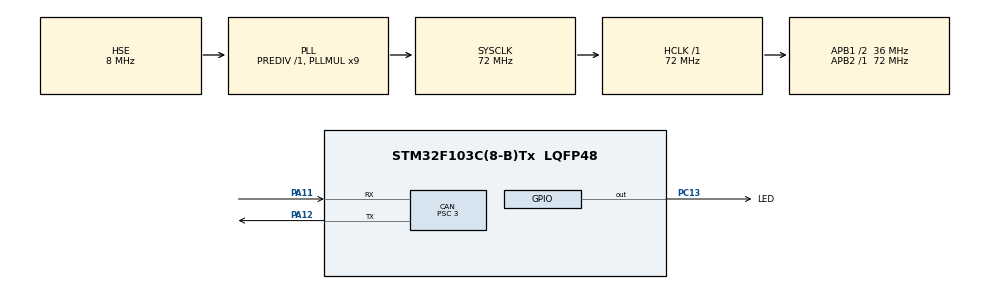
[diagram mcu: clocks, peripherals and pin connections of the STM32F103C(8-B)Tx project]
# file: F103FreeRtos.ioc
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CAN.BS1=CAN_BS1_9TQ
CAN.BS2=CAN_BS2_2TQ
CAN.CalculateTimeBit=1000
CAN.CalculateTimeQuantum=83.33333333333334
CAN.Prescaler=3
FREERTOS.Tasks01=defaultTask,0,128,StartDefaultTask,Default,NULL
Mcu.Family=STM32F1
Mcu.Name=STM32F103C(8-B)Tx
Mcu.Package=LQFP48
NVIC.PriorityGroup=NVIC_PRIORITYGROUP_4
NVIC.TIM4_IRQn=true\:0\:0\:false\:false\:true\:false\:false\:true
NVIC.TimeBase=TIM4_IRQn
NVIC.TimeBaseIP=TIM4
PA11.Mode=Master
PA11.Signal=CAN_RX
PA12.Mode=Master
PA12.Signal=CAN_TX
PA13.Mode=Serial_Wire
PA13.Signal=SYS_JTMS-SWDIO
PA14.Mode=Serial_Wire
PA14.Signal=SYS_JTCK-SWCLK
PC13-TAMPER-RTC.GPIO_Label=LED
PC13-TAMPER-RTC.Signal=GPIO_Output
PC14-OSC32_IN.Mode=LSE-External-Oscillator
PC14-OSC32_IN.Signal=RCC_OSC32_IN
PC15-OSC32_OUT.Mode=LSE-External-Oscillator
PC15-OSC32_OUT.Signal=RCC_OSC32_OUT
PD0-OSC_IN.Mode=HSE-External-Oscillator
PD0-OSC_IN.Signal=RCC_OSC_IN
PD1-OSC_OUT.Mode=HSE-External-Oscillator
PD1-OSC_OUT.Signal=RCC_OSC_OUT
ProjectManager.HeapSize=0x200
ProjectManager.StackSize=0x400
ProjectManager.TargetToolchain=Makefile
RCC.AHBFreq_Value=72000000
RCC.APB1CLKDivider=RCC_HCLK_DIV2
RCC.APB1Freq_Value=36000000
RCC.APB1TimFreq_Value=72000000
RCC.APB2Freq_Value=72000000
RCC.APB2TimFreq_Value=72000000
RCC.HCLKFreq_Value=72000000
RCC.PLLMUL=RCC_PLL_MUL9
RCC.PLLSourceVirtual=RCC_PLLSOURCE_HSE
RCC.SYSCLKFreq_VALUE=72000000
RCC.SYSCLKSource=RCC_SYSCLKSOURCE_PLLCLK
RCC.USBFreq_Value=72000000
VP_FREERTOS_VS_CMSIS_V1.Mode=CMSIS_V1
VP_SYS_VS_tim4.Mode=TIM4
board=custom

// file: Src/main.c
/* USER CODE BEGIN Header */
/**
  ******************************************************************************
  * @file           : main.c
  * @brief          : Main program body
  ******************************************************************************
  * @attention
  *
  * <h2><center>&copy; Copyright (c) 2019 STMicroelectronics.
  * All rights reserved.</center></h2>
  *
  * This software component is licensed by ST under Ultimate Liberty license
  * SLA0044, the "License"; You may not use this file except in compliance with
  * the License. You may obtain a copy of the License at:
  *                             www.st.com/SLA0044
  *
  ******************************************************************************
  */
/* USER CODE END Header */

#include "main.h"
#include "cmsis_os.h"

CAN_HandleTypeDef hcan;

osThreadId defaultTaskHandle;

void SystemClock_Config(void);
static void MX_GPIO_Init(void);
static void MX_CAN_Init(void);
void StartDefaultTask(void const * argument);

int main(void)
{

  /* MCU Configuration--------------------------------------------------------*/

  /* Reset of all peripherals, Initializes the Flash interface and the Systick. */
  HAL_Init();

  /* Configure the system clock */
  SystemClock_Config();

  /* Initialize all configured peripherals */
  MX_GPIO_Init();
  MX_CAN_Init();

  /* Create the thread(s) */
  /* definition and creation of defaultTask */
  osThreadDef(defaultTask, StartDefaultTask, osPriorityNormal, 0, 128);
  defaultTaskHandle = osThreadCreate(osThread(defaultTask), NULL);

  /* Start scheduler */
  osKernelStart();

  /* We should never get here as control is now taken by the scheduler */

  /* Infinite loop */
  while (1)
  {

  }
}

void SystemClock_Config(void)
{
  RCC_OscInitTypeDef RCC_OscInitStruct = {0};
  RCC_ClkInitTypeDef RCC_ClkInitStruct = {0};

  /** Initializes the CPU, AHB and APB busses clocks
  */
  RCC_OscInitStruct.OscillatorType = RCC_OSCILLATORTYPE_HSE;
  RCC_OscInitStruct.HSEState = RCC_HSE_ON;
  RCC_OscInitStruct.HSEPredivValue = RCC_HSE_PREDIV_DIV1;
  RCC_OscInitStruct.HSIState = RCC_HSI_ON;
  RCC_OscInitStruct.PLL.PLLState = RCC_PLL_ON;
  RCC_OscInitStruct.PLL.PLLSource = RCC_PLLSOURCE_HSE;
  RCC_OscInitStruct.PLL.PLLMUL = RCC_PLL_MUL9;
  if (HAL_RCC_OscConfig(&RCC_OscInitStruct) != HAL_OK)
  {
    Error_Handler();
  }
  /** Initializes the CPU, AHB and APB busses clocks
  */
  RCC_ClkInitStruct.ClockType = RCC_CLOCKTYPE_HCLK|RCC_CLOCKTYPE_SYSCLK
                              |RCC_CLOCKTYPE_PCLK1|RCC_CLOCKTYPE_PCLK2;
  RCC_ClkInitStruct.SYSCLKSource = RCC_SYSCLKSOURCE_PLLCLK;
  RCC_ClkInitStruct.AHBCLKDivider = RCC_SYSCLK_DIV1;
  RCC_ClkInitStruct.APB1CLKDivider = RCC_HCLK_DIV2;
  RCC_ClkInitStruct.APB2CLKDivider = RCC_HCLK_DIV1;

  if (HAL_RCC_ClockConfig(&RCC_ClkInitStruct, FLASH_LATENCY_2) != HAL_OK)
  {
    Error_Handler();
  }
}

static void MX_CAN_Init(void)
{

  hcan.Instance = CAN1;
  hcan.Init.Prescaler = 3;
  hcan.Init.Mode = CAN_MODE_NORMAL;
  hcan.Init.SyncJumpWidth = CAN_SJW_1TQ;
  hcan.Init.TimeSeg1 = CAN_BS1_9TQ;
  hcan.Init.TimeSeg2 = CAN_BS2_2TQ;
  hcan.Init.TimeTriggeredMode = DISABLE;
  hcan.Init.AutoBusOff = DISABLE;
  hcan.Init.AutoWakeUp = DISABLE;
  hcan.Init.AutoRetransmission = DISABLE;
  hcan.Init.ReceiveFifoLocked = DISABLE;
  hcan.Init.TransmitFifoPriority = DISABLE;
  if (HAL_CAN_Init(&hcan) != HAL_OK)
  {
    Error_Handler();
  }

}

static void MX_GPIO_Init(void)
{
  GPIO_InitTypeDef GPIO_InitStruct = {0};

  /* GPIO Ports Clock Enable */
  __HAL_RCC_GPIOC_CLK_ENABLE();
  __HAL_RCC_GPIOD_CLK_ENABLE();
  __HAL_RCC_GPIOA_CLK_ENABLE();

  /*Configure GPIO pin Output Level */
  HAL_GPIO_WritePin(LED_GPIO_Port, LED_Pin, GPIO_PIN_RESET);

  /*Configure GPIO pin : LED_Pin */
  GPIO_InitStruct.Pin = LED_Pin;
  GPIO_InitStruct.Mode = GPIO_MODE_OUTPUT_PP;
  GPIO_InitStruct.Pull = GPIO_NOPULL;
  GPIO_InitStruct.Speed = GPIO_SPEED_FREQ_LOW;
  HAL_GPIO_Init(LED_GPIO_Port, &GPIO_InitStruct);

}

void StartDefaultTask(void const * argument)
{

  /* USER CODE BEGIN 5 */

  static CAN_TxHeaderTypeDef header =
      {
          .StdId = 0x300,
          .IDE = CAN_ID_STD,
          .RTR = CAN_RTR_DATA,
          .DLC = 8};
  uint8_t data[8];
  uint32_t mailbox;
  /* Infinite loop */
  for (;;)
  {
    HAL_CAN_AddTxMessage(&hcan, &header, data, &mailbox);
    HAL_GPIO_TogglePin(LED_GPIO_Port, LED_Pin);
    osDelay(100);
  }
  /* USER CODE END 5 */
}

void HAL_TIM_PeriodElapsedCallback(TIM_HandleTypeDef *htim)
{
  if (htim->Instance == TIM4) {
    HAL_IncTick();
  }
}

void Error_Handler(void)
{
}

/************************ (C) COPYRIGHT STMicroelectronics *****END OF FILE****/
